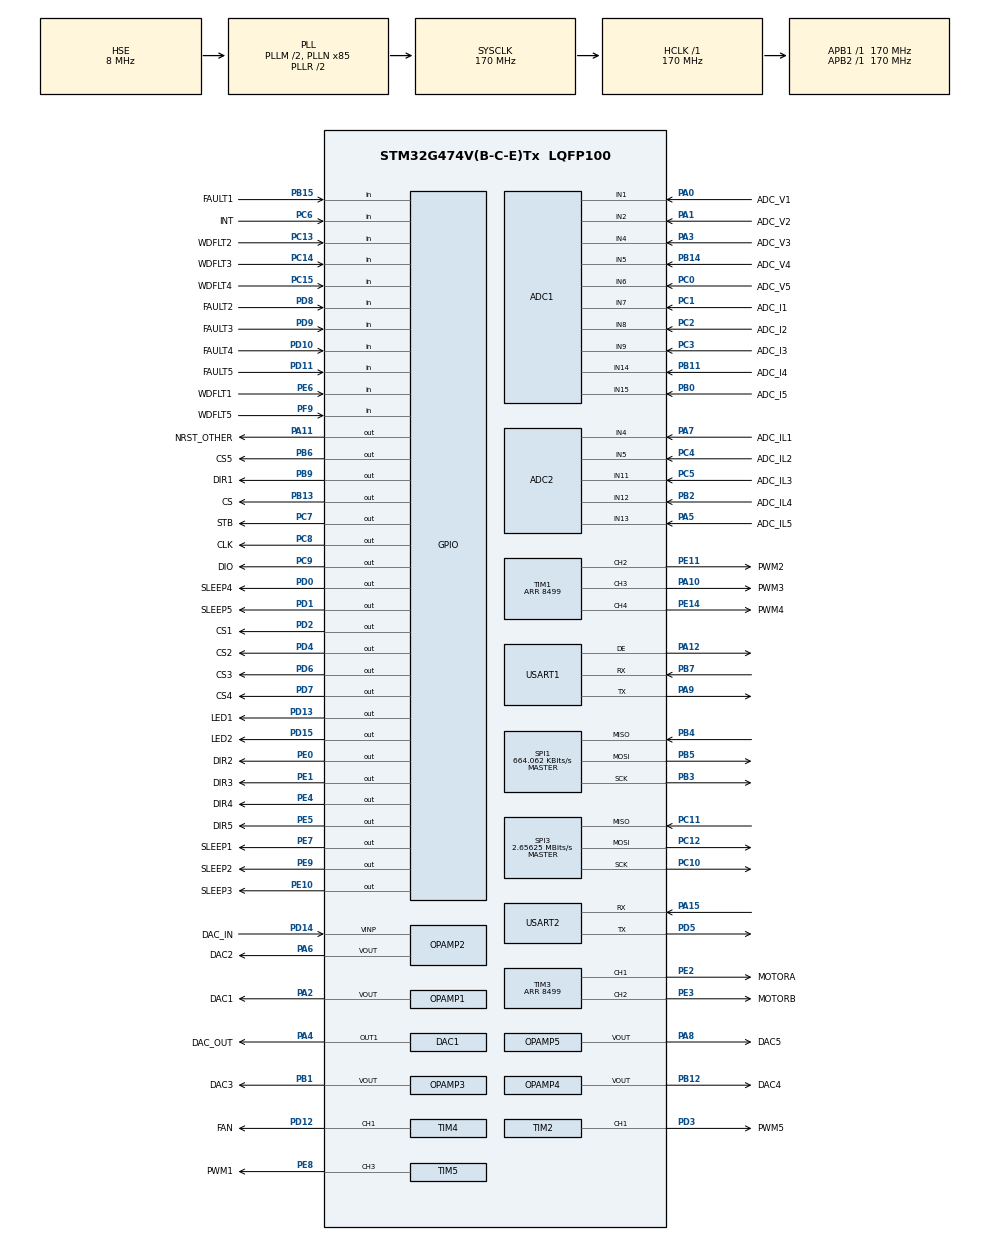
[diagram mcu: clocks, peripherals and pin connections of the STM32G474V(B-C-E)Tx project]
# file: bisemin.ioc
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ADC1.Channel-0\#ChannelRegularConversion=ADC_CHANNEL_1
ADC1.Channel-1\#ChannelRegularConversion=ADC_CHANNEL_2
ADC1.Channel-2\#ChannelRegularConversion=ADC_CHANNEL_4
ADC1.Channel-3\#ChannelRegularConversion=ADC_CHANNEL_5
ADC1.Channel-4\#ChannelRegularConversion=ADC_CHANNEL_6
ADC1.Channel-5\#ChannelRegularConversion=ADC_CHANNEL_7
ADC1.Channel-6\#ChannelRegularConversion=ADC_CHANNEL_8
ADC1.Channel-7\#ChannelRegularConversion=ADC_CHANNEL_9
ADC1.Channel-8\#ChannelRegularConversion=ADC_CHANNEL_14
ADC1.Channel-9\#ChannelRegularConversion=ADC_CHANNEL_15
ADC1.DMAContinuousRequests=ENABLE
ADC1.EOCSelection=ADC_EOC_SEQ_CONV
ADC1.ExternalTrigConv=ADC_EXTERNALTRIG_T7_TRGO
ADC1.NbrOfConversion=10
ADC1.NbrOfConversionFlag=1
ADC1.OffsetNumber-0\#ChannelRegularConversion=ADC_OFFSET_NONE
ADC1.OffsetNumber-1\#ChannelRegularConversion=ADC_OFFSET_NONE
ADC1.OffsetNumber-2\#ChannelRegularConversion=ADC_OFFSET_NONE
ADC1.OffsetNumber-3\#ChannelRegularConversion=ADC_OFFSET_NONE
ADC1.OffsetNumber-4\#ChannelRegularConversion=ADC_OFFSET_NONE
ADC1.OffsetNumber-5\#ChannelRegularConversion=ADC_OFFSET_NONE
ADC1.OffsetNumber-6\#ChannelRegularConversion=ADC_OFFSET_NONE
ADC1.OffsetNumber-7\#ChannelRegularConversion=ADC_OFFSET_NONE
ADC1.OffsetNumber-8\#ChannelRegularConversion=ADC_OFFSET_NONE
ADC1.OffsetNumber-9\#ChannelRegularConversion=ADC_OFFSET_NONE
ADC1.Rank-0\#ChannelRegularConversion=1
ADC1.Rank-1\#ChannelRegularConversion=2
ADC1.Rank-2\#ChannelRegularConversion=3
ADC1.Rank-3\#ChannelRegularConversion=4
ADC1.Rank-4\#ChannelRegularConversion=5
ADC1.Rank-5\#ChannelRegularConversion=6
ADC1.Rank-6\#ChannelRegularConversion=7
ADC1.Rank-7\#ChannelRegularConversion=8
ADC1.Rank-8\#ChannelRegularConversion=9
ADC1.Rank-9\#ChannelRegularConversion=10
ADC1.SamplingTime-0\#ChannelRegularConversion=ADC_SAMPLETIME_2CYCLES_5
ADC1.SamplingTime-1\#ChannelRegularConversion=ADC_SAMPLETIME_2CYCLES_5
ADC1.SamplingTime-2\#ChannelRegularConversion=ADC_SAMPLETIME_2CYCLES_5
ADC1.SamplingTime-3\#ChannelRegularConversion=ADC_SAMPLETIME_2CYCLES_5
ADC1.SamplingTime-4\#ChannelRegularConversion=ADC_SAMPLETIME_2CYCLES_5
ADC1.SamplingTime-5\#ChannelRegularConversion=ADC_SAMPLETIME_2CYCLES_5
ADC1.SamplingTime-6\#ChannelRegularConversion=ADC_SAMPLETIME_2CYCLES_5
ADC1.SamplingTime-7\#ChannelRegularConversion=ADC_SAMPLETIME_2CYCLES_5
ADC1.SamplingTime-8\#ChannelRegularConversion=ADC_SAMPLETIME_2CYCLES_5
ADC1.SamplingTime-9\#ChannelRegularConversion=ADC_SAMPLETIME_2CYCLES_5
ADC1.master=1
ADC2.Channel-0\#ChannelRegularConversion=ADC_CHANNEL_4
ADC2.Channel-1\#ChannelRegularConversion=ADC_CHANNEL_5
ADC2.Channel-2\#ChannelRegularConversion=ADC_CHANNEL_11
ADC2.Channel-3\#ChannelRegularConversion=ADC_CHANNEL_12
ADC2.Channel-4\#ChannelRegularConversion=ADC_CHANNEL_13
ADC2.DMAContinuousRequests=ENABLE
ADC2.EOCSelection=ADC_EOC_SEQ_CONV
ADC2.ExternalTrigConv=ADC_EXTERNALTRIG_T1_TRGO2
ADC2.NbrOfConversion=5
ADC2.NbrOfConversionFlag=1
ADC2.OffsetNumber-0\#ChannelRegularConversion=ADC_OFFSET_NONE
ADC2.OffsetNumber-1\#ChannelRegularConversion=ADC_OFFSET_NONE
ADC2.OffsetNumber-2\#ChannelRegularConversion=ADC_OFFSET_NONE
ADC2.OffsetNumber-3\#ChannelRegularConversion=ADC_OFFSET_NONE
ADC2.OffsetNumber-4\#ChannelRegularConversion=ADC_OFFSET_NONE
ADC2.Rank-0\#ChannelRegularConversion=1
ADC2.Rank-1\#ChannelRegularConversion=2
ADC2.Rank-2\#ChannelRegularConversion=3
ADC2.Rank-3\#ChannelRegularConversion=4
ADC2.Rank-4\#ChannelRegularConversion=5
ADC2.SamplingTime-0\#ChannelRegularConversion=ADC_SAMPLETIME_2CYCLES_5
ADC2.SamplingTime-1\#ChannelRegularConversion=ADC_SAMPLETIME_2CYCLES_5
ADC2.SamplingTime-2\#ChannelRegularConversion=ADC_SAMPLETIME_2CYCLES_5
ADC2.SamplingTime-3\#ChannelRegularConversion=ADC_SAMPLETIME_2CYCLES_5
ADC2.SamplingTime-4\#ChannelRegularConversion=ADC_SAMPLETIME_2CYCLES_5
DAC3.DAC_Channel-DAC_OUT2_Int=DAC_CHANNEL_2
DAC4.DAC_Channel-DAC_OUT2_Int=DAC_CHANNEL_2
Dma.ADC1.2.Direction=DMA_PERIPH_TO_MEMORY
Dma.ADC1.2.EventEnable=DISABLE
Dma.ADC1.2.Instance=DMA1_Channel3
Dma.ADC1.2.MemDataAlignment=DMA_MDATAALIGN_HALFWORD
Dma.ADC1.2.MemInc=DMA_MINC_ENABLE
Dma.ADC1.2.Mode=DMA_CIRCULAR
Dma.ADC1.2.PeriphDataAlignment=DMA_PDATAALIGN_HALFWORD
Dma.ADC1.2.PeriphInc=DMA_PINC_DISABLE
Dma.ADC1.2.Polarity=HAL_DMAMUX_REQ_GEN_RISING
Dma.ADC1.2.Priority=DMA_PRIORITY_LOW
Dma.ADC1.2.RequestNumber=1
Dma.ADC1.2.SignalID=NONE
Dma.ADC1.2.SyncEnable=DISABLE
Dma.ADC1.2.SyncPolarity=HAL_DMAMUX_SYNC_NO_EVENT
Dma.ADC1.2.SyncRequestNumber=1
Dma.ADC1.2.SyncSignalID=NONE
Dma.ADC2.0.Direction=DMA_PERIPH_TO_MEMORY
Dma.ADC2.0.EventEnable=DISABLE
Dma.ADC2.0.Instance=DMA1_Channel1
Dma.ADC2.0.MemDataAlignment=DMA_MDATAALIGN_HALFWORD
Dma.ADC2.0.MemInc=DMA_MINC_ENABLE
Dma.ADC2.0.Mode=DMA_CIRCULAR
Dma.ADC2.0.PeriphDataAlignment=DMA_PDATAALIGN_HALFWORD
Dma.ADC2.0.PeriphInc=DMA_PINC_DISABLE
Dma.ADC2.0.Polarity=HAL_DMAMUX_REQ_GEN_RISING
Dma.ADC2.0.Priority=DMA_PRIORITY_LOW
Dma.ADC2.0.RequestNumber=1
Dma.ADC2.0.SignalID=NONE
Dma.ADC2.0.SyncEnable=DISABLE
Dma.ADC2.0.SyncPolarity=HAL_DMAMUX_SYNC_NO_EVENT
Dma.ADC2.0.SyncRequestNumber=1
Dma.ADC2.0.SyncSignalID=NONE
Dma.Request0=ADC2
Dma.Request1=USART1_RX
Dma.Request2=ADC1
Dma.USART1_RX.1.Direction=DMA_PERIPH_TO_MEMORY
Dma.USART1_RX.1.EventEnable=DISABLE
Dma.USART1_RX.1.Instance=DMA1_Channel2
Dma.USART1_RX.1.MemDataAlignment=DMA_MDATAALIGN_BYTE
Dma.USART1_RX.1.MemInc=DMA_MINC_ENABLE
Dma.USART1_RX.1.Mode=DMA_NORMAL
Dma.USART1_RX.1.PeriphDataAlignment=DMA_PDATAALIGN_BYTE
Dma.USART1_RX.1.PeriphInc=DMA_PINC_DISABLE
Dma.USART1_RX.1.Polarity=HAL_DMAMUX_REQ_GEN_RISING
Dma.USART1_RX.1.Priority=DMA_PRIORITY_LOW
Dma.USART1_RX.1.RequestNumber=1
Dma.USART1_RX.1.SignalID=NONE
Dma.USART1_RX.1.SyncEnable=DISABLE
Dma.USART1_RX.1.SyncPolarity=HAL_DMAMUX_SYNC_NO_EVENT
Dma.USART1_RX.1.SyncRequestNumber=1
Dma.USART1_RX.1.SyncSignalID=NONE
FREERTOS.Mutexes01=SysStateMutex,Dynamic,NULL,Available
FREERTOS.Tasks01=ControlTask,40,512,StartControlTask,Default,NULL,Dynamic,NULL,NULL;HMITask,8,256,StartHMITask,Default,NULL,Dynamic,NULL,NULL
FREERTOS.configTOTAL_HEAP_SIZE=8192
Mcu.Family=STM32G4
Mcu.Name=STM32G474V(B-C-E)Tx
Mcu.Package=LQFP100
NVIC.DMA1_Channel1_IRQn=true\:5\:0\:false\:false\:true\:true\:false\:true\:true
NVIC.DMA1_Channel2_IRQn=true\:5\:0\:false\:false\:true\:true\:false\:true\:true
NVIC.DMA1_Channel3_IRQn=true\:5\:0\:false\:false\:true\:true\:false\:true\:true
NVIC.PriorityGroup=NVIC_PRIORITYGROUP_4
NVIC.TIM6_DAC_IRQn=true\:15\:0\:false\:false\:true\:false\:false\:true\:true
NVIC.TimeBase=TIM6_DAC_IRQn
NVIC.TimeBaseIP=TIM6
NVIC.USART1_IRQn=true\:7\:0\:true\:false\:true\:true\:true\:true\:true
PA0.GPIO_Label=ADC_V1
PA0.Mode=IN1-Single-Ended
PA0.Signal=ADC1_IN1
PA1.GPIO_Label=ADC_V2
PA1.Mode=IN2-Single-Ended
PA1.Signal=ADC1_IN2
PA10.GPIO_Label=PWM3
PA10.Signal=S_TIM1_CH3
PA11.GPIO_Label=NRST_OTHER
PA11.Signal=GPIO_Output
PA12.Mode=Hardware Flow Control (RS485)
PA12.Signal=USART1_DE
PA13.Mode=Serial_Wire
PA13.Signal=SYS_JTMS-SWDIO
PA14.Mode=Serial_Wire
PA14.Signal=SYS_JTCK-SWCLK
PA15.Mode=Asynchronous
PA15.Signal=USART2_RX
PA2.GPIO_Label=DAC1
PA2.Mode=Follower-DAC_OUT2-INP
PA2.Signal=OPAMP1_VOUT
PA3.GPIO_Label=ADC_V3
PA3.Mode=IN4-Single-Ended
PA3.Signal=ADC1_IN4
PA4.GPIO_Label=DAC_OUT
PA4.Signal=COMP_DAC11_group
PA5.GPIO_Label=ADC_IL5
PA5.Mode=IN13-Single-Ended
PA5.Signal=ADC2_IN13
PA6.GPIO_Label=DAC2
PA6.Mode=Follower
PA6.Signal=OPAMP2_VOUT
PA7.GPIO_Label=ADC_IL1
PA7.Mode=IN4-Single-Ended
PA7.Signal=ADC2_IN4
PA8.GPIO_Label=DAC5
PA8.Mode=Follower-DAC_OUT2-INP
PA8.Signal=OPAMP5_VOUT
PA9.Mode=Asynchronous
PA9.Signal=USART1_TX
PB0.GPIO_Label=ADC_I5
PB0.Mode=IN15-Single-Ended
PB0.Signal=ADC1_IN15
PB1.GPIO_Label=DAC3
PB1.Mode=Follower-DAC_OUT2-INP
PB1.Signal=OPAMP3_VOUT
PB11.GPIO_Label=ADC_I4
PB11.Mode=IN14-Single-Ended
PB11.Signal=ADC1_IN14
PB12.GPIO_Label=DAC4
PB12.Mode=Follower-DAC_OUT2-INP
PB12.Signal=OPAMP4_VOUT
PB13.GPIO_Label=CS
PB13.Signal=GPIO_Output
PB14.GPIO_Label=ADC_V4
PB14.Mode=IN5-Single-Ended
PB14.Signal=ADC1_IN5
PB15.GPIO_Label=FAULT1
PB15.Signal=GPIO_Input
PB2.GPIO_Label=ADC_IL4
PB2.Mode=IN12-Single-Ended
PB2.Signal=ADC2_IN12
PB3.Mode=Full_Duplex_Master
PB3.Signal=SPI1_SCK
PB4.Mode=Full_Duplex_Master
PB4.Signal=SPI1_MISO
PB5.Mode=Full_Duplex_Master
PB5.Signal=SPI1_MOSI
PB6.GPIO_Label=CS5
PB6.Signal=GPIO_Output
PB7.Mode=Asynchronous
PB7.Signal=USART1_RX
PB9.GPIO_Label=DIR1
PB9.Signal=GPIO_Output
PC0.GPIO_Label=ADC_V5
PC0.Mode=IN6-Single-Ended
PC0.Signal=ADC1_IN6
PC1.GPIO_Label=ADC_I1
PC1.Mode=IN7-Single-Ended
PC1.Signal=ADC1_IN7
PC10.Mode=Full_Duplex_Master
PC10.Signal=SPI3_SCK
PC11.Mode=Full_Duplex_Master
PC11.Signal=SPI3_MISO
PC12.Mode=Full_Duplex_Master
PC12.Signal=SPI3_MOSI
PC13.GPIO_Label=WDFLT2
PC13.Signal=GPIO_Input
PC14-OSC32_IN.GPIO_Label=WDFLT3
PC14-OSC32_IN.Signal=GPIO_Input
PC15-OSC32_OUT.GPIO_Label=WDFLT4
PC15-OSC32_OUT.Signal=GPIO_Input
PC2.GPIO_Label=ADC_I2
PC2.Mode=IN8-Single-Ended
PC2.Signal=ADC1_IN8
PC3.GPIO_Label=ADC_I3
PC3.Mode=IN9-Single-Ended
PC3.Signal=ADC1_IN9
PC4.GPIO_Label=ADC_IL2
PC4.Mode=IN5-Single-Ended
PC4.Signal=ADC2_IN5
PC5.GPIO_Label=ADC_IL3
PC5.Mode=IN11-Single-Ended
PC5.Signal=ADC2_IN11
PC6.GPIO_Label=INT
PC6.Signal=GPIO_Input
PC7.GPIO_Label=STB
PC7.Signal=GPIO_Output
PC8.GPIO_Label=CLK
PC8.Signal=GPIO_Output
PC9.GPIO_Label=DIO
PC9.Signal=GPIO_Output
PD0.GPIO_Label=SLEEP4
PD0.Signal=GPIO_Output
PD1.GPIO_Label=SLEEP5
PD1.Signal=GPIO_Output
PD10.GPIO_Label=FAULT4
PD10.Signal=GPIO_Input
PD11.GPIO_Label=FAULT5
PD11.Signal=GPIO_Input
PD12.GPIO_Label=FAN
PD12.Signal=S_TIM4_CH1
PD13.GPIO_Label=LED1
PD13.Signal=GPIO_Output
PD14.GPIO_Label=DAC_IN
PD14.Mode=Follower
PD14.Signal=OPAMP2_VINP
PD15.GPIO_Label=LED2
PD15.Signal=GPIO_Output
PD2.GPIO_Label=CS1
PD2.Signal=GPIO_Output
PD3.GPIO_Label=PWM5
PD3.Signal=S_TIM2_CH1
PD4.GPIO_Label=CS2
PD4.Signal=GPIO_Output
PD5.Mode=Asynchronous
PD5.Signal=USART2_TX
PD6.GPIO_Label=CS3
PD6.Signal=GPIO_Output
PD7.GPIO_Label=CS4
PD7.Signal=GPIO_Output
PD8.GPIO_Label=FAULT2
PD8.Signal=GPIO_Input
PD9.GPIO_Label=FAULT3
PD9.Signal=GPIO_Input
PE0.GPIO_Label=DIR2
PE0.Signal=GPIO_Output
PE1.GPIO_Label=DIR3
PE1.Signal=GPIO_Output
PE10.GPIO_Label=SLEEP3
PE10.Signal=GPIO_Output
PE11.GPIO_Label=PWM2
PE11.Signal=S_TIM1_CH2
PE14.GPIO_Label=PWM4
PE14.Signal=S_TIM1_CH4
PE2.GPIO_Label=MOTORA
PE2.Signal=S_TIM3_CH1
PE3.GPIO_Label=MOTORB
PE3.Signal=S_TIM3_CH2
PE4.GPIO_Label=DIR4
PE4.Signal=GPIO_Output
PE5.GPIO_Label=DIR5
PE5.Signal=GPIO_Output
PE6.GPIO_Label=WDFLT1
PE6.Signal=GPIO_Input
PE7.GPIO_Label=SLEEP1
PE7.Signal=GPIO_Output
PE8.GPIO_Label=PWM1
PE8.Signal=S_TIM5_CH3
PE9.GPIO_Label=SLEEP2
PE9.Signal=GPIO_Output
PF0-OSC_IN.Mode=HSE-External-Oscillator
PF0-OSC_IN.Signal=RCC_OSC_IN
PF1-OSC_OUT.Mode=HSE-External-Oscillator
PF1-OSC_OUT.Signal=RCC_OSC_OUT
PF9.GPIO_Label=WDFLT5
PF9.Signal=GPIO_Input
ProjectManager.HeapSize=0x2000
ProjectManager.StackSize=0x8000
ProjectManager.TargetToolchain=MDK-ARM V5.32
RCC.ADC12Freq_Value=170000000
RCC.ADC345Freq_Value=170000000
RCC.AHBFreq_Value=170000000
RCC.APB1Freq_Value=170000000
RCC.APB1TimFreq_Value=170000000
RCC.APB2Freq_Value=170000000
RCC.APB2TimFreq_Value=170000000
RCC.CortexFreq_Value=170000000
RCC.EXTERNAL_CLOCK_VALUE=12288000
RCC.HCLKFreq_Value=170000000
RCC.HSE_VALUE=8000000
RCC.HSI48_VALUE=48000000
RCC.HSI_VALUE=16000000
RCC.LSE_VALUE=32768
RCC.PLLM=RCC_PLLM_DIV2
RCC.PLLN=85
RCC.PLLSourceVirtual=RCC_PLLSOURCE_HSE
RCC.SYSCLKFreq_VALUE=170000000
RCC.SYSCLKSource=RCC_SYSCLKSOURCE_PLLCLK
RCC.USBFreq_Value=170000000
RCC.VCOOutputFreq_Value=340000000
SH.COMP_DAC11_group.0=DAC1_OUT1,DAC_OUT1
SH.S_TIM1_CH2.0=TIM1_CH2,PWM Generation2 CH2
SH.S_TIM1_CH3.0=TIM1_CH3,PWM Generation3 CH3
SH.S_TIM1_CH4.0=TIM1_CH4,PWM Generation4 CH4
SH.S_TIM2_CH1.0=TIM2_CH1,PWM Generation1 CH1
SH.S_TIM3_CH1.0=TIM3_CH1,PWM Generation1 CH1
SH.S_TIM3_CH2.0=TIM3_CH2,PWM Generation2 CH2
SH.S_TIM4_CH1.0=TIM4_CH1,PWM Generation1 CH1
SH.S_TIM5_CH3.0=TIM5_CH3,PWM Generation3 CH3
SPI1.BaudRatePrescaler=SPI_BAUDRATEPRESCALER_256
SPI1.CLKPhase=SPI_PHASE_2EDGE
SPI1.CalculateBaudRate=664.062 KBits/s
SPI1.DataSize=SPI_DATASIZE_8BIT
SPI1.Direction=SPI_DIRECTION_2LINES
SPI1.Mode=SPI_MODE_MASTER
SPI1.VirtualType=VM_MASTER
SPI3.BaudRatePrescaler=SPI_BAUDRATEPRESCALER_64
SPI3.CalculateBaudRate=2.65625 MBits/s
SPI3.Direction=SPI_DIRECTION_2LINES
SPI3.Mode=SPI_MODE_MASTER
SPI3.VirtualType=VM_MASTER
TIM1.Channel-PWM\ Generation2\ CH2=TIM_CHANNEL_2
TIM1.Channel-PWM\ Generation3\ CH3=TIM_CHANNEL_3
TIM1.Channel-PWM\ Generation4\ CH4=TIM_CHANNEL_4
TIM1.Channel-PWM\ Generation5\ No\ Output=TIM_CHANNEL_5
TIM1.OCMode_PWM-PWM\ Generation5\ No\ Output=TIM_OCMODE_PWM2
TIM1.PeriodNoDither=8499
TIM1.TIM_MasterOutputTrigger=TIM_TRGO_UPDATE
TIM1.TIM_MasterOutputTrigger2=TIM_TRGO2_OC5REF
TIM1.TIM_MasterSlaveMode=TIM_MASTERSLAVEMODE_DISABLE
TIM2.Channel-PWM\ Generation1\ CH1=TIM_CHANNEL_1
TIM2.PeriodNoDither=8499
TIM3.Channel-PWM\ Generation1\ CH1=TIM_CHANNEL_1
TIM3.Channel-PWM\ Generation2\ CH2=TIM_CHANNEL_2
TIM3.PeriodNoDither=8499
TIM4.Channel-PWM\ Generation1\ CH1=TIM_CHANNEL_1
TIM4.PeriodNoDither=6000
TIM5.Channel-PWM\ Generation3\ CH3=TIM_CHANNEL_3
TIM5.PeriodNoDither=8499
TIM7.PeriodNoDither=1000-1
TIM7.Prescaler=170-1
TIM7.TIM_MasterOutputTrigger=TIM_TRGO_UPDATE
USART1.VirtualMode-Asynchronous=VM_ASYNC
USART1.VirtualMode-Hardware\ Flow\ Control\ (RS485)=VM_ASYNC
USART2.VirtualMode-Asynchronous=VM_ASYNC
VP_DAC3_VS_DACI1.Mode=DAC_OUT1_Int
VP_DAC3_VS_DACI2.Mode=DAC_OUT2_Int
VP_DAC4_VS_DACI1.Mode=DAC_OUT1_Int
VP_DAC4_VS_DACI2.Mode=DAC_OUT2_Int
VP_FREERTOS_VS_CMSIS_V2.Mode=CMSIS_V2
VP_SYS_VS_DBSignals.Mode=DisableDeadBatterySignals
VP_SYS_VS_tim6.Mode=TIM6
VP_TIM1_VS_ClockSourceINT.Mode=Internal
VP_TIM1_VS_no_output5.Mode=PWM Generation5 No Output
VP_TIM2_VS_ClockSourceINT.Mode=Internal
VP_TIM2_VS_ClockSourceITR.Mode=TriggerSource_ITR0
VP_TIM2_VS_ControllerModeReset.Mode=Reset Mode
VP_TIM3_VS_ClockSourceINT.Mode=Internal
VP_TIM4_VS_ClockSourceINT.Mode=Internal
VP_TIM5_VS_ClockSourceINT.Mode=Internal
VP_TIM5_VS_ClockSourceITR.Mode=TriggerSource_ITR0
VP_TIM5_VS_ControllerModeReset.Mode=Reset Mode
VP_TIM7_VS_ClockSourceINT.Mode=Enable_Timer
board=custom

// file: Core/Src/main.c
/* USER CODE BEGIN Header */
/**
 ******************************************************************************
 * @file           : main.c
 * @brief          : Main program body
 ******************************************************************************
 * @attention
 *
 * Copyright (c) 2026 STMicroelectronics.
 * All rights reserved.
 *
 * This software is licensed under terms that can be found in the LICENSE file
 * in the root directory of this software component.
 * If no LICENSE file comes with this software, it is provided AS-IS.
 *
 ******************************************************************************
 */
/* USER CODE END Header */
#include "main.h"
#include "cmsis_os.h"
#include "adc.h"
#include "dac.h"
#include "dma.h"
#include "opamp.h"
#include "spi.h"
#include "tim.h"
#include "usart.h"
#include "gpio.h"

/* USER CODE BEGIN Includes */
#include "bridge1_test.h"
#include "tm1638_board.h"
#include "pid_controller.h"
#include "temp_panel.h"
/* USER CODE END Includes */

/* USER CODE BEGIN PM */
uint8_t g_reg0 = 0;
uint8_t g_reg1 = 0;
uint8_t g_reg2 = 0;
uint8_t g_reg3 = 0;
uint8_t g_reg4 = 0;
uint8_t g_reg5 = 0;
uint8_t g_reg2_lock = 0;
uint8_t g_reg2_unlock = 0;
uint8_t g_reg3_after = 0;
/* USER CODE END PM */

/* USER CODE BEGIN PV */
volatile float Sys_Temperatures[4] = {0.0f};
volatile uint8_t Sys_Status[4] = {0};
volatile uint32_t Sys_TempUpdateCount[4] = {0};
volatile uint32_t Sys_TempUpdateTick[4] = {0};
volatile uint8_t g_uart_need_restart = 0U;
#define RX_BUFFER_SIZE 256
uint8_t rx_buffer[RX_BUFFER_SIZE];
uint16_t rx_length = 0;
int8_t flag_temp_update = 0;
PID_TypeDef temp_pid;
/* USER CODE END PV */

void SystemClock_Config(void);
void MX_FREERTOS_Init(void);

/* USER CODE BEGIN 0 */
void Parse_Temperature_Buffer(uint8_t *pData, uint16_t Size);
void Parse_Temperature_Byte(uint8_t rx_byte);
/* ── 长按检测 ── */
static uint32_t key_hold_start[KEY_MAX_NUM] = {0};
static uint32_t key_last_repeat[KEY_MAX_NUM] = {0};
static bool key_long_sent[KEY_MAX_NUM] = {false};

/* 按键回调: 仅在按下瞬间触发 SHORT 事件, 同时记录 hold 起始时刻 */
static void OnTM1638Key(TM1638_Key_t key)
{
  PanelKey_t pk = PanelKey_FromTM1638(key);
  if (pk == PANEL_KEY_NONE)
    return;

  uint32_t now = osKernelGetTickCount();
  key_hold_start[key] = now;
  key_last_repeat[key] = 0;
  key_long_sent[key] = false;
  TempPanel_KeyEvent(&g_panel, pk, PANEL_KEY_EVT_SHORT, now);
}

/*
 * 长按/连发检测: 需在主循环或 HMITask 中每 20ms 调用,
 * 紧跟在 TM1638_ProcessKeys() 之后。
 */
void CheckKeyHoldEvents(void)
{
  uint32_t now = osKernelGetTickCount();
  for (int i = 0; i < KEY_MAX_NUM; i++)
  {
    PanelKey_t pk = PanelKey_FromTM1638((TM1638_Key_t)i);
    if (pk == PANEL_KEY_NONE)
      continue;

    if (htm1638.key_states[i])
    {
      if (key_hold_start[i] == 0)
        continue;

      uint32_t held = now - key_hold_start[i];

      /* 按住 > 2s 触发一次 LONG */
      if (held >= 2000)
      {
        if (!key_long_sent[i])
        {
          TempPanel_KeyEvent(&g_panel, pk, PANEL_KEY_EVT_LONG, now);
          key_long_sent[i] = true;
        }
      }
      /* 按住 > 500ms 开始连发, 每 150ms 一次 REPEAT */
      if (held >= 500)
      {
        if (key_last_repeat[i] == 0 || now - key_last_repeat[i] >= 150)
        {
          TempPanel_KeyEvent(&g_panel, pk, PANEL_KEY_EVT_REPEAT, now);
          key_last_repeat[i] = now;
        }
      }
    }
    else
    {
      key_hold_start[i] = 0;
      key_last_repeat[i] = 0;
      key_long_sent[i] = false;
    }
  }
}

void OnModeKeyPressed(void) { OnTM1638Key(KEY_MODE); }
void OnStartStopKeyPressed(void) { OnTM1638Key(KEY_START_STOP); }
void OnUpKeyPressed(void) { OnTM1638Key(KEY_UP); }
void OnDownKeyPressed(void) { OnTM1638Key(KEY_DOWN); }
void OnEnterKeyPressed(void) { OnTM1638Key(KEY_ENTER); }
void OnSwitchKeyPressed(void) { OnTM1638Key(KEY_SWITCH); }
uint8_t DRV8703_ReadReg1(uint8_t addr)
{
  uint8_t tx[2];
  uint8_t rx[2];
  uint16_t frame;

  /*
   * DRV8703 读命令：
   * bit15 = 1
   * bit14~11 = addr
   */
  frame = 0x8000U | ((uint16_t)(addr & 0x0F) << 11);

  tx[0] = (uint8_t)(frame >> 8);
  tx[1] = (uint8_t)(frame & 0xFF);

  rx[0] = 0;
  rx[1] = 0;

  HAL_GPIO_WritePin(CS1_GPIO_Port, CS1_Pin, GPIO_PIN_RESET);

  HAL_SPI_TransmitReceive(&hspi1, tx, rx, 2, 100);

  HAL_GPIO_WritePin(CS1_GPIO_Port, CS1_Pin, GPIO_PIN_SET);

  /*
   * 返回低 8 bit
   */
  return rx[1];
}
void DRV8703_WriteReg1(uint8_t addr, uint8_t data)
{
  uint8_t tx[2];
  uint8_t rx[2];
  uint16_t frame;

  /*
   * DRV8703 写命令：
   * bit15 = 0
   * bit14~11 = addr
   * bit7~0 = data
   */
  frame = ((uint16_t)(addr & 0x0F) << 11) | data;

  tx[0] = (uint8_t)(frame >> 8);
  tx[1] = (uint8_t)(frame & 0xFF);

  rx[0] = 0;
  rx[1] = 0;

  HAL_GPIO_WritePin(CS1_GPIO_Port, CS1_Pin, GPIO_PIN_RESET);

  HAL_SPI_TransmitReceive(&hspi1, tx, rx, 2, 100);

  HAL_GPIO_WritePin(CS1_GPIO_Port, CS1_Pin, GPIO_PIN_SET);
}
/* USER CODE END 0 */

int main(void)
{

  /* MCU Configuration--------------------------------------------------------*/

  /* Reset of all peripherals, Initializes the Flash interface and the Systick. */
  HAL_Init();

  /* Configure the system clock */
  SystemClock_Config();

  /* Initialize all configured peripherals */
  MX_GPIO_Init();
  MX_DMA_Init();
  MX_ADC1_Init();
  MX_ADC2_Init();
  MX_DAC1_Init();
  MX_DAC3_Init();
  MX_DAC4_Init();
  MX_OPAMP1_Init();
  MX_OPAMP2_Init();
  MX_OPAMP3_Init();
  MX_OPAMP4_Init();
  MX_OPAMP5_Init();
  MX_TIM1_Init();
  MX_SPI1_Init();
  MX_TIM2_Init();
  MX_TIM3_Init();
  MX_TIM4_Init();
  MX_USART1_UART_Init();
  MX_USART2_UART_Init();
  MX_SPI3_Init();
  MX_TIM5_Init();
  MX_TIM7_Init();
  /* USER CODE BEGIN 2 */
  // 开启 TIM3 的 PWM 输出，开启水泵的电机
  HAL_TIM_PWM_Start(&htim3, TIM_CHANNEL_1);
  HAL_TIM_PWM_Start(&htim3, TIM_CHANNEL_2);
  __HAL_TIM_SetCompare(&htim3, TIM_CHANNEL_1, 8499);
  __HAL_TIM_SetCompare(&htim3, TIM_CHANNEL_2, 4000);

  // 启动带有空闲检测的 DMA 接收
  // 启动 USART2 带有空闲检测的 DMA 接收
  TemperatureUart_RestartReceive();
  // 直接通过 huart2 结构体内部的 hdmarx 指针来关闭过半中断
  HAL_Delay(20);
  HAL_GPIO_WritePin(NRST_OTHER_GPIO_Port, NRST_OTHER_Pin, GPIO_PIN_SET);

  /* 一键初始化: TM1638 + Panel + PID + 默认显示 */
  Panel_Init();

  /* 注册所有按键回调 */
  TM1638_RegisterKeyCallback(&htm1638, KEY_MODE, OnModeKeyPressed);
  TM1638_RegisterKeyCallback(&htm1638, KEY_START_STOP, OnStartStopKeyPressed);
  TM1638_RegisterKeyCallback(&htm1638, KEY_UP, OnUpKeyPressed);
  TM1638_RegisterKeyCallback(&htm1638, KEY_DOWN, OnDownKeyPressed);
  TM1638_RegisterKeyCallback(&htm1638, KEY_ENTER, OnEnterKeyPressed);
  TM1638_RegisterKeyCallback(&htm1638, KEY_SWITCH, OnSwitchKeyPressed);
  // HAL_DAC_Start(&hdac3, DAC_CHANNEL_1);
  // HAL_DAC_SetValue(&hdac3, DAC_CHANNEL_1, DAC_ALIGN_12B_R,
  //                  (uint32_t)(1000.0f * 4095.0f / 3300.0f));
  // HAL_OPAMP_Start(&hopamp1);

  //  Bridge1_StartHoldTest(0.05f, 1000);

  // HAL_TIM_PWM_Start(&htim3, TIM_CHANNEL_2);
  // __HAL_TIM_SetCompare(&htim3, TIM_CHANNEL_2, 150);

  //  HAL_GPIO_WritePin(SLEEP1_GPIO_Port, SLEEP1_Pin, GPIO_PIN_SET);
  //  HAL_Delay(20);

  //  /* 所有其它 SPI 片选都拉高 */
  //  HAL_GPIO_WritePin(CS1_GPIO_Port, CS1_Pin, GPIO_PIN_SET);
  //  /* ADS1220_CS 也要拉高 */
  //  /* CS2/CS3/CS4/CS5 也要拉高 */

  //  /* 读默认寄存器 */
  //  g_reg0 = DRV8703_ReadReg1(0x00);
  //  g_reg1 = DRV8703_ReadReg1(0x01);
  //  g_reg2 = DRV8703_ReadReg1(0x02);
  //  g_reg3 = DRV8703_ReadReg1(0x03);
  //  g_reg4 = DRV8703_ReadReg1(0x04);
  //  g_reg5 = DRV8703_ReadReg1(0x05);

  //  /* 测试 Reg2 写入 */
  //  DRV8703_WriteReg1(0x02, 0x30);
  //  HAL_Delay(2);
  //  g_reg2_lock = DRV8703_ReadReg1(0x02);

  //  DRV8703_WriteReg1(0x02, 0x18);
  //  HAL_Delay(2);
  //  g_reg2_unlock = DRV8703_ReadReg1(0x02);

  //  /* 测试 Reg3 写入 */
  //  DRV8703_WriteReg1(0x03, 0xC7);
  //  HAL_Delay(2);
  //  g_reg3_after = DRV8703_ReadReg1(0x03);
  /* USER CODE END 2 */

  /* Init scheduler */
  osKernelInitialize(); /* Call init function for freertos objects (in cmsis_os2.c) */
  MX_FREERTOS_Init();

  /* Start scheduler */
  osKernelStart();

  /* We should never get here as control is now taken by the scheduler */

  /* Infinite loop */
  while (1)
  {

  }
}

void SystemClock_Config(void)
{
  RCC_OscInitTypeDef RCC_OscInitStruct = {0};
  RCC_ClkInitTypeDef RCC_ClkInitStruct = {0};

  /** Configure the main internal regulator output voltage
   */
  HAL_PWREx_ControlVoltageScaling(PWR_REGULATOR_VOLTAGE_SCALE1_BOOST);

  /** Initializes the RCC Oscillators according to the specified parameters
   * in the RCC_OscInitTypeDef structure.
   */
  RCC_OscInitStruct.OscillatorType = RCC_OSCILLATORTYPE_HSE;
  RCC_OscInitStruct.HSEState = RCC_HSE_ON;
  RCC_OscInitStruct.PLL.PLLState = RCC_PLL_ON;
  RCC_OscInitStruct.PLL.PLLSource = RCC_PLLSOURCE_HSE;
  RCC_OscInitStruct.PLL.PLLM = RCC_PLLM_DIV2;
  RCC_OscInitStruct.PLL.PLLN = 85;
  RCC_OscInitStruct.PLL.PLLP = RCC_PLLP_DIV2;
  RCC_OscInitStruct.PLL.PLLQ = RCC_PLLQ_DIV2;
  RCC_OscInitStruct.PLL.PLLR = RCC_PLLR_DIV2;
  if (HAL_RCC_OscConfig(&RCC_OscInitStruct) != HAL_OK)
  {
    Error_Handler();
  }

  /** Initializes the CPU, AHB and APB buses clocks
   */
  RCC_ClkInitStruct.ClockType = RCC_CLOCKTYPE_HCLK | RCC_CLOCKTYPE_SYSCLK | RCC_CLOCKTYPE_PCLK1 | RCC_CLOCKTYPE_PCLK2;
  RCC_ClkInitStruct.SYSCLKSource = RCC_SYSCLKSOURCE_PLLCLK;
  RCC_ClkInitStruct.AHBCLKDivider = RCC_SYSCLK_DIV1;
  RCC_ClkInitStruct.APB1CLKDivider = RCC_HCLK_DIV1;
  RCC_ClkInitStruct.APB2CLKDivider = RCC_HCLK_DIV1;

  if (HAL_RCC_ClockConfig(&RCC_ClkInitStruct, FLASH_LATENCY_4) != HAL_OK)
  {
    Error_Handler();
  }
}

/* USER CODE BEGIN 4 */
void TemperatureUart_RestartReceive(void)
{
  (void)HAL_UART_AbortReceive(&huart1);
  (void)HAL_UARTEx_ReceiveToIdle_DMA(&huart1, rx_buffer, RX_BUFFER_SIZE);
  if (huart1.hdmarx != NULL)
  {
    __HAL_DMA_DISABLE_IT(huart1.hdmarx, DMA_IT_HT);
  }
}

void HAL_UARTEx_RxEventCallback(UART_HandleTypeDef *huart, uint16_t Size)
{
  if (huart->Instance == USART1)
  {
    /* Parse temperature data */
    Parse_Temperature_Buffer(rx_buffer, Size);

    /*
     * Restart DMA idle-line reception directly in the ISR.
     * The idle line means the current frame is complete and DMA has stopped,
     * so we do NOT need HAL_UART_AbortReceive (which is blocking).
     * Just start a new DMA reception immediately.
     */
    (void)HAL_UARTEx_ReceiveToIdle_DMA(&huart1, rx_buffer, RX_BUFFER_SIZE);
    if (huart1.hdmarx != NULL)
    {
      __HAL_DMA_DISABLE_IT(huart1.hdmarx, DMA_IT_HT);
    }
  }
}

/**
 * @brief  字节级协议解析状态机 (自动处理粘包/断包)
 * @param  rx_byte 接收到的单字节
 */
void Parse_Temperature_Byte(uint8_t rx_byte)
{
  static uint8_t state = 0;
  static uint8_t frame_buf[9];
  static uint8_t idx = 0;

  switch (state)
  {
  case 0: // 寻找帧头 1
    if (rx_byte == 0xAA)
    {
      frame_buf[0] = rx_byte;
      state = 1;
    }
    break;

  case 1: // 寻找帧头 2
    if (rx_byte == 0x55)
    {
      frame_buf[1] = rx_byte;
      idx = 2;
      state = 2;
    }
    else if (rx_byte == 0xAA)
    {
      state = 1; // 容错：连续收到两个 AA
    }
    else
    {
      state = 0; // 帧头错误，状态机复位
    }
    break;

  case 2: // 接收数据体与校验和
    frame_buf[idx++] = rx_byte;

    if (idx >= 9)
    { // 收集满一帧 9 字节
      // 1. 计算校验和
      uint8_t sum = 0;
      for (int i = 2; i <= 7; i++)
      {
        sum += frame_buf[i];
      }

      // 2. 验证校验和
      if (sum == frame_buf[8])
      {
        uint8_t ch_id = frame_buf[2];  // 通道号 1~4
        uint8_t status = frame_buf[3]; // 状态位

        // 3. 提取并保存数据
        if (ch_id >= 1 && ch_id <= 4)
        {
          Sys_Status[ch_id - 1] = status; // 保存状态

          if (status == 0)
          {
            // 状态正常时，提取浮点温度数据
            float temp_val;
            uint8_t *pTemp = (uint8_t *)&temp_val;
            pTemp[0] = frame_buf[4];
            pTemp[1] = frame_buf[5];
            pTemp[2] = frame_buf[6];
            pTemp[3] = frame_buf[7];

            // 存入全局温度数组
            Sys_Temperatures[ch_id - 1] = temp_val;
            Sys_TempUpdateCount[ch_id - 1]++;
            Sys_TempUpdateTick[ch_id - 1] = HAL_GetTick();

            // printf("CH%d OK: %.4f\r\n", ch_id, temp_val);
            if (ch_id == 2) // 如果是 CH2 的温度更新了，设置标志让主循环计算 PID 输出
            {
              flag_temp_update = 1;
            }
          }
          else
          {
            // 如果状态为 1 (断开/超时)，为了安全，可以把该通道温度设为一个异常值 (例如 -999.0)
            // Sys_Temperatures[ch_id - 1] = -999.0f;
          }
        }
      }
      // 解析完毕，状态机归零，准备迎接下一帧
      state = 0;
    }
    break;
  }
}

/**
 * @brief  数据块解析函数 (供空闲中断调用)
 * @param  pData 接收到的数据首地址
 * @param  Size  接收到的数据长度
 */
void Parse_Temperature_Buffer(uint8_t *pData, uint16_t Size)
{
  for (uint16_t i = 0; i < Size; i++)
  {
    Parse_Temperature_Byte(pData[i]); // 将数据块逐字节喂给状态机
  }
}
/* USER CODE END 4 */

void HAL_TIM_PeriodElapsedCallback(TIM_HandleTypeDef *htim)
{
  if (htim->Instance == TIM6)
  {
    HAL_IncTick();
  }
}

void Error_Handler(void)
{
  __disable_irq();
  while (1)
  {
  }
}

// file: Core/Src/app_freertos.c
/* USER CODE BEGIN Header */
/**
 ******************************************************************************
 * File Name          : app_freertos.c
 * Description        : Code for freertos applications
 ******************************************************************************
 */
/* USER CODE END Header */

#include "FreeRTOS.h"
#include "task.h"
#include "main.h"
#include "cmsis_os.h"

/* USER CODE BEGIN Includes */
#include "drv8703_board.h"
#include "opamp.h"
#include "adc.h"
#include "dac.h"
#include "usart.h"
#include "gpio.h"
#include "string.h"
#include "stdio.h"
#include "stdlib.h"
#include "math.h"
#include "stdbool.h"
#include "tim.h"
#include "temp_panel.h"
#include "tm1638_board.h"
#include "sys_state.h"
#include "adc_measure.h"
#include "app_control.h"
/* USER CODE END Includes */

/* USER CODE BEGIN PD */
#define DRV8703_EXAMPLE_CHANNEL DRV8703_BOARD_CH1
#define DRV8703_EXAMPLE_VREF_MV 2000U
#define DRV8703_EXAMPLE_DUTY 0.40f
#define APP_ADC_MEASURE_ZERO_SAMPLES 64U
/* USER CODE END PD */

/* USER CODE BEGIN Variables */
volatile uint8_t g_app_drv8703_selected_channel = DRV8703_EXAMPLE_CHANNEL;
volatile DRV8703_Status_t g_app_drv8703_init_result = DRV8703_ERROR_PARAM;
volatile DRV8703_Status_t g_app_drv8703_config_result = DRV8703_ERROR_PARAM;
volatile DRV8703_Status_t g_app_drv8703_start_result = DRV8703_ERROR_PARAM;
volatile DRV8703_Status_t g_app_drv8703_monitor_result = DRV8703_ERROR_PARAM;
volatile DRV8703_Status_t g_app_drv8703_read_fault_result = DRV8703_ERROR_PARAM;
volatile DRV8703_Status_t g_app_drv8703_dump_result = DRV8703_ERROR_PARAM;
volatile uint8_t g_app_drv8703_loop_counter = 0;
DRV8703_FaultInfo_t g_app_drv8703_fault_info = {0xFFU, 0xFFU};
uint8_t g_app_drv8703_reg_dump[DRV8703_REGISTER_COUNT] = {0};
volatile HAL_StatusTypeDef g_app_tim_sync_start_result = HAL_OK;
volatile uint32_t g_app_tim1_trgo2_compare = 0U;
volatile AdcMeasure_Status_t g_app_adc_measure_start_result = ADC_MEASURE_ERROR_ADC1;
volatile AppControl_Status_t g_app_control_start_result = APP_CONTROL_ERROR_QUEUE;
/* USER CODE END Variables */
/* Definitions for ControlTask */
osThreadId_t ControlTaskHandle;
const osThreadAttr_t ControlTask_attributes = {
    .name = "ControlTask",
    .priority = (osPriority_t)osPriorityHigh,
    .stack_size = 512 * 4};
/* Definitions for HMITask */
osThreadId_t HMITaskHandle;
const osThreadAttr_t HMITask_attributes = {
    .name = "HMITask",
    .priority = (osPriority_t)osPriorityLow,
    .stack_size = 256 * 4};
/* Definitions for SysStateMutex */
osMutexId_t SysStateMutexHandle;
const osMutexAttr_t SysStateMutex_attributes = {
    .name = "SysStateMutex"};

/* USER CODE BEGIN FunctionPrototypes */
static HAL_StatusTypeDef App_StartSynchronizedPwmTimebase(void);
/* USER CODE END FunctionPrototypes */

void StartControlTask(void *argument);
void StartHMITask(void *argument);

void MX_FREERTOS_Init(void); /* (MISRA C 2004 rule 8.1) */

void MX_FREERTOS_Init(void)
{
  /* Create the mutex(es) */
  /* creation of SysStateMutex */
  SysStateMutexHandle = osMutexNew(&SysStateMutex_attributes);

  /* Create the thread(s) */
  /* creation of ControlTask */
  ControlTaskHandle = osThreadNew(StartControlTask, NULL, &ControlTask_attributes);

  /* creation of HMITask */
  HMITaskHandle = osThreadNew(StartHMITask, NULL, &HMITask_attributes);

}

void StartControlTask(void *argument)
{
  /* USER CODE BEGIN StartControlTask */
  (void)argument;

  osDelay(1000);

  g_app_tim_sync_start_result = App_StartSynchronizedPwmTimebase();
  g_app_adc_measure_start_result = AdcMeasure_Start();
  if (g_app_adc_measure_start_result == ADC_MEASURE_OK)
  {
    AdcMeasure_CalibrateCurrentZero(APP_ADC_MEASURE_ZERO_SAMPLES);
  }
  g_app_control_start_result = AppControl_Init();

  /* Infinite loop */
  for (;;)
  {
    AdcMeasure_Process();
    AppControl_Task(osKernelGetTickCount());

    /*
     * Keil Watch:
     * g_app_control_*              control task status
     * g_adc_v1_input_v ~ g_adc_v5_input_v
     * g_adc_i1_a       ~ g_adc_i5_a
     * g_adc_il1_a      ~ g_adc_il5_a
     * g_adc_measure_adc1_update_count / g_adc_measure_adc2_update_count
     */
    g_app_drv8703_loop_counter++;
    osDelay(20);
  }
  /* USER CODE END StartControlTask */
}

void StartHMITask(void *argument)
{
  /* USER CODE BEGIN StartHMITask */
  // (void)argument;
  // uint8_t led8_on = 0U;

  // TM1638_SetAllLEDs(&htm1638, 0U);

  // for (;;)
  // {
  //   led8_on ^= 1U;
  //   TM1638_SetLED(&htm1638, 8U, led8_on != 0U);
  //   osDelay(1000);
  // }

#if 1
  uint32_t now;
  static uint32_t last_tick = 0;

  for (;;)
  {
    now = osKernelGetTickCount();

    if (now - last_tick >= 20)
    {
      last_tick = now;
      TM1638_ProcessKeys(&htm1638);
      CheckKeyHoldEvents();
      AppControl_UpdatePanel(&g_panel, now);
      TempPanel_Task(&g_panel, now);

      static uint32_t last_blink = 0;
      if (now - last_blink >= 500)
      {
        last_blink = now;
        HAL_GPIO_TogglePin(LED2_GPIO_Port, LED2_Pin);
      }
    }

    osDelay(5);
  }
#endif
  /* USER CODE END StartHMITask */
}

/* USER CODE BEGIN Application */
static HAL_StatusTypeDef App_TIM_BaseStartIfStopped(TIM_HandleTypeDef *htim)
{
  if ((htim->Instance->CR1 & TIM_CR1_CEN) != 0U)
  {
    return HAL_OK;
  }

  return HAL_TIM_Base_Start(htim);
}

static HAL_StatusTypeDef App_StartSynchronizedPwmTimebase(void)
{
  HAL_StatusTypeDef ret;
  uint32_t arr;

  __HAL_TIM_SET_COMPARE(&htim1, TIM_CHANNEL_2, 0U);
  __HAL_TIM_SET_COMPARE(&htim1, TIM_CHANNEL_3, 0U);
  __HAL_TIM_SET_COMPARE(&htim1, TIM_CHANNEL_4, 0U);
  __HAL_TIM_SET_COMPARE(&htim2, TIM_CHANNEL_1, 0U);
  __HAL_TIM_SET_COMPARE(&htim5, TIM_CHANNEL_3, 0U);

  /*
   * TIM1 TRGO2 is OC5REF. CH5 has no pin output, so it is only used as
   * the ADC2 sampling trigger. PWM2 + CCR5 at mid-period gives a rising
   * edge near the middle of the PWM cycle.
   */
  arr = __HAL_TIM_GET_AUTORELOAD(&htim1);
  g_app_tim1_trgo2_compare = (arr + 1U) / 2U;
  __HAL_TIM_SET_COMPARE(&htim1, TIM_CHANNEL_5, g_app_tim1_trgo2_compare);

  __HAL_TIM_SET_COUNTER(&htim2, 0U);
  __HAL_TIM_SET_COUNTER(&htim5, 0U);
  __HAL_TIM_SET_COUNTER(&htim1, 0U);

  ret = App_TIM_BaseStartIfStopped(&htim2);
  if (ret != HAL_OK)
  {
    return ret;
  }

  ret = App_TIM_BaseStartIfStopped(&htim5);
  if (ret != HAL_OK)
  {
    return ret;
  }

  return App_TIM_BaseStartIfStopped(&htim1);
}
/* USER CODE END Application */
